# ATSAME51J18A register map
Vendor: Microchip Technology; Series: SAME51; File version: 0
CPU: CM4 r0p1, selectable endian, MPU, FPU, 3 interrupt priority bits
Registers are 32-bit, read-write, reset 0x0 unless marked. A register's access mark holds for its fields unless they carry their own. Offsets are from the block's base; [hi:lo] are bit positions; lines under a group give offsets from that group; {n}, {i} and the like mark numbered series; 'fields as' and 'values as' point back to an identical list.

## USB — Universal Serial Bus
Base 0x41000000; register names take the prefix USB_
0x00 DEVICE group — USB is Device
  0x00 CTRLA 8-bit — Control A
    [7] MODE — Operating Mode
      0=DEVICE (Device Mode); 1=HOST (Host Mode)
    [2] RUNSTDBY — Run in Standby Mode
    [1] ENABLE
    [0] SWRST — Software Reset
  0x02 SYNCBUSY 8-bit ro — Synchronization Busy
    [1] ENABLE — Enable Synchronization Busy
    [0] SWRST — Software Reset Synchronization Busy
  0x03 QOSCTRL 8-bit reset 0xF — USB Quality Of Service
    [3:2] DQOS — Data Quality of Service
    [1:0] CQOS — Configuration Quality of Service
  0x08 CTRLB 16-bit reset 0x1 — DEVICE Control B
    [11:10] LPMHDSK — Link Power Management Handshake
      0=NO (No handshake. LPM is not supported); 1=ACK; 2=NYET; 3=STALL
    [9] GNAK — Global NAK
    [8] OPMODE2 — Specific Operational Mode
    [7] TSTPCKT — Test packet mode
    [6] TSTK — Test mode K
    [5] TSTJ — Test mode J
    [4] NREPLY — No Reply
    [3:2] SPDCONF — Speed Configuration
      0=FS (FS : Full Speed); 1=LS (LS : Low Speed); 2=HS (HS : High Speed capable); 3=HSTM (HSTM: High Speed Test Mode (force high-speed mode for test mode))
    [1] UPRSM — Upstream Resume
    [0] DETACH
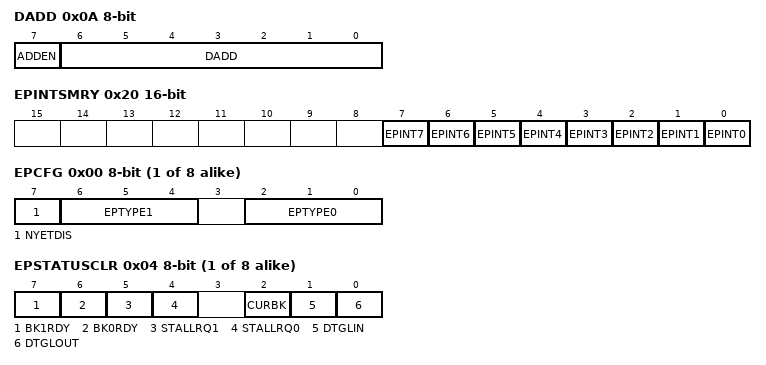
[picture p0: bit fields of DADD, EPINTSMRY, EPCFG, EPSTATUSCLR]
  0x0A DADD 8-bit — DEVICE Device Address
    [7] ADDEN — Device Address Enable
    [6:0] DADD — Device Address
  0x0C STATUS 8-bit ro reset 0x40 — DEVICE Status
    [7:6] LINESTATE — USB Line State Status
      0=SE0/RESET; 1=FS-J or LS-K State; 2=FS-K or LS-J State
    [3:2] SPEED — Speed Status
      0=FS (Full-speed mode); 1=LS (Low-speed mode); 2=HS (High-speed mode)
  0x0D FSMSTATUS 8-bit ro reset 0x1 — Finite State Machine Status
    [6:0] FSMSTATE — Fine State Machine Status
      1=OFF (OFF (L3). It corresponds to the powered-off, disconnected, and disabled state); 2=ON (ON (L0). It corresponds to the Idle and Active states); 4=SUSPEND (SUSPEND (L2)); 8=SLEEP (SLEEP (L1)); 16=DNRESUME (DNRESUME. Down Stream Resume.); 32=UPRESUME (UPRESUME. Up Stream Resume.); 64=RESET (RESET. USB lines Reset.)
  0x10 FNUM 16-bit ro — DEVICE Device Frame Number
    [15] FNCERR — Frame Number CRC Error
    [13:3] FNUM — Frame Number
    [2:0] MFNUM — Micro Frame Number
  0x14 INTENCLR 16-bit — DEVICE Device Interrupt Enable Clear
    [9] LPMSUSP — Link Power Management Suspend Interrupt Enable
    [8] LPMNYET — Link Power Management Not Yet Interrupt Enable
    [7] RAMACER — Ram Access Interrupt Enable
    [6] UPRSM — Upstream Resume Interrupt Enable
    [5] EORSM — End Of Resume Interrupt Enable
    [4] WAKEUP — Wake Up Interrupt Enable
    [3] EORST — End of Reset Interrupt Enable
    [2] SOF — Start Of Frame Interrupt Enable
    [1] MSOF — Micro Start of Frame Interrupt Enable in High Speed Mode
    [0] SUSPEND — Suspend Interrupt Enable
  0x18 INTENSET 16-bit — DEVICE Device Interrupt Enable Set
    fields as DEVICE.INTENCLR
  0x1C INTFLAG 16-bit — DEVICE Device Interrupt Flag
    [9] LPMSUSP write-1-clears — Link Power Management Suspend
    [8] LPMNYET write-1-clears — Link Power Management Not Yet
    [7] RAMACER write-1-clears — Ram Access
    [6] UPRSM write-1-clears — Upstream Resume
    [5] EORSM write-1-clears — End Of Resume
    [4] WAKEUP write-1-clears
    [3] EORST write-1-clears — End of Reset
    [2] SOF write-1-clears — Start Of Frame
    [1] MSOF — Micro Start of Frame in High Speed Mode
    [0] SUSPEND write-1-clears
  0x20 EPINTSMRY 16-bit ro — DEVICE End Point Interrupt Summary
    [n] EPINT{n} (n=0..7) — End Point {n} Interrupt
  0x24 DESCADD — Descriptor Address
    [31:0] DESCADD — Descriptor Address Value
  0x28 PADCAL 16-bit — USB PAD Calibration
    [14:12] TRIM — USB Pad Trim calibration
    [10:6] TRANSN — USB Pad Transn calibration
    [4:0] TRANSP — USB Pad Transp calibration
  {0x100+0x20*j} DEVICE_ENDPOINT[{j}] (j=0..7) group
    0x00 EPCFG 8-bit — DEVICE_ENDPOINT End Point Configuration
      [7] NYETDIS — NYET Token Disable
      [6:4] EPTYPE1 — End Point Type1
      [2:0] EPTYPE0 — End Point Type0
    0x04 EPSTATUSCLR 8-bit wo — DEVICE_ENDPOINT End Point Pipe Status Clear
      [7] BK1RDY — Bank 1 Ready Clear
      [6] BK0RDY — Bank 0 Ready Clear
      [5] STALLRQ1 — Stall 1 Request Clear
      [4] STALLRQ0 — Stall 0 Request Clear
      [2] CURBK — Current Bank Clear
      [1] DTGLIN — Data Toggle IN Clear
      [0] DTGLOUT — Data Toggle OUT Clear
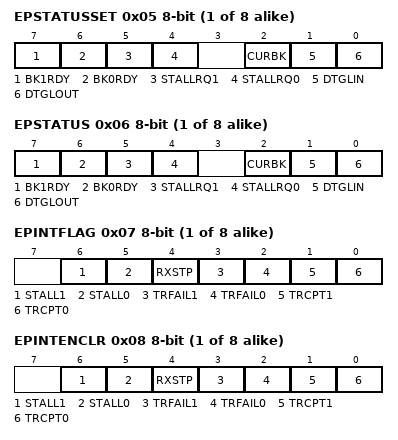
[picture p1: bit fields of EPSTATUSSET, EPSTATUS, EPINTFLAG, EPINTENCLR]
    0x05 EPSTATUSSET 8-bit wo — DEVICE_ENDPOINT End Point Pipe Status Set
      [7] BK1RDY — Bank 1 Ready Set
      [6] BK0RDY — Bank 0 Ready Set
      [5] STALLRQ1 — Stall 1 Request Set
      [4] STALLRQ0 — Stall 0 Request Set
      [2] CURBK — Current Bank Set
      [1] DTGLIN — Data Toggle IN Set
      [0] DTGLOUT — Data Toggle OUT Set
    0x06 EPSTATUS 8-bit ro — DEVICE_ENDPOINT End Point Pipe Status
      [7] BK1RDY — Bank 1 ready
      [6] BK0RDY — Bank 0 ready
      [5] STALLRQ1 — Stall 1 Request
      [4] STALLRQ0 — Stall 0 Request
      [2] CURBK — Current Bank
      [1] DTGLIN — Data Toggle In
      [0] DTGLOUT — Data Toggle Out
    0x07 EPINTFLAG 8-bit — DEVICE_ENDPOINT End Point Interrupt Flag
      [6] STALL1 write-1-clears — Stall 1 In/out
      [5] STALL0 write-1-clears — Stall 0 In/out
      [4] RXSTP write-1-clears — Received Setup
      [3] TRFAIL1 write-1-clears — Error Flow 1
      [2] TRFAIL0 write-1-clears — Error Flow 0
      [1] TRCPT1 write-1-clears — Transfer Complete 1
      [0] TRCPT0 write-1-clears — Transfer Complete 0
    0x08 EPINTENCLR 8-bit — DEVICE_ENDPOINT End Point Interrupt Clear Flag
      [6] STALL1 — Stall 1 In/Out Interrupt Disable
      [5] STALL0 — Stall 0 In/Out Interrupt Disable
      [4] RXSTP — Received Setup Interrupt Disable
      [3] TRFAIL1 — Error Flow 1 Interrupt Disable
      [2] TRFAIL0 — Error Flow 0 Interrupt Disable
      [1] TRCPT1 — Transfer Complete 1 Interrupt Disable
      [0] TRCPT0 — Transfer Complete 0 Interrupt Disable
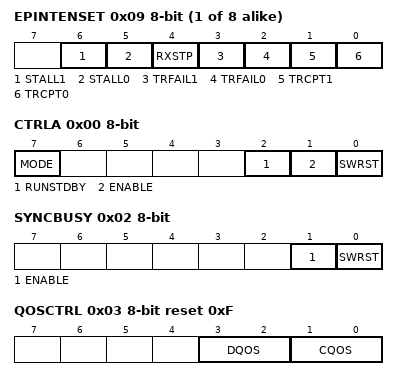
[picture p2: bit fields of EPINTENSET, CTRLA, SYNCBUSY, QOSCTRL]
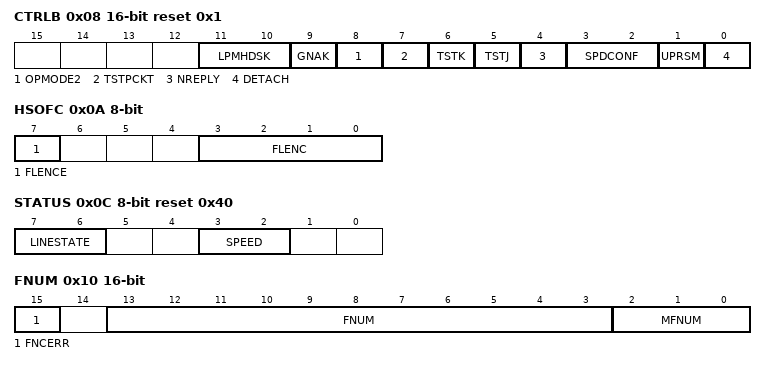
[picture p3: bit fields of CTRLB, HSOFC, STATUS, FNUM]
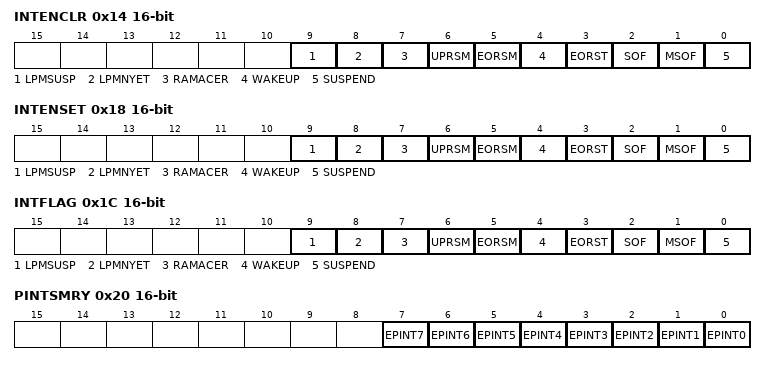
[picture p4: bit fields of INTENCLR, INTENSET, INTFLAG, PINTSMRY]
    0x09 EPINTENSET 8-bit — DEVICE_ENDPOINT End Point Interrupt Set Flag
      [6] STALL1 — Stall 1 In/out Interrupt enable
      [5] STALL0 — Stall 0 In/out Interrupt enable
      [4] RXSTP — Received Setup Interrupt Enable
      [3] TRFAIL1 — Error Flow 1 Interrupt Enable
      [2] TRFAIL0 — Error Flow 0 Interrupt Enable
      [1] TRCPT1 — Transfer Complete 1 Interrupt Enable
      [0] TRCPT0 — Transfer Complete 0 Interrupt Enable
0x00 HOST group (alternate view of DEVICE) — USB is Host
  0x00 CTRLA 8-bit — Control A
    fields as DEVICE.CTRLA
  0x02 SYNCBUSY 8-bit ro — Synchronization Busy
    fields as DEVICE.SYNCBUSY
  0x03 QOSCTRL 8-bit reset 0xF — USB Quality Of Service
    fields as DEVICE.QOSCTRL
  0x08 CTRLB 16-bit — HOST Control B
    [11] L1RESUME — Send L1 Resume
    [10] VBUSOK — VBUS is OK
    [9] BUSRESET — Send USB Reset
    [8] SOFE — Start of Frame Generation Enable
    [6] TSTK — Test mode K
    [5] TSTJ — Test mode J
    [4] AUTORESUME — Auto Resume Enable
    [3:2] SPDCONF — Speed Configuration for Host
      0=NORMAL (Normal mode: the host starts in full-speed mode and performs a high-speed reset to switch to the high speed mode if the downstream peripheral is high-speed capable.); 3=FS (Full-speed: the host remains in full-speed mode whatever is the peripheral speed capability. Relevant in UTMI mode only.)
    [1] RESUME — Send USB Resume
  0x0A HSOFC 8-bit — HOST Host Start Of Frame Control
    [7] FLENCE — Frame Length Control Enable
    [3:0] FLENC — Frame Length Control
  0x0C STATUS 8-bit — HOST Status
    [7:6] LINESTATE — USB Line State Status
    [3:2] SPEED — Speed Status
  0x0D FSMSTATUS 8-bit ro reset 0x1 — Finite State Machine Status
    fields as DEVICE.FSMSTATUS
  0x10 FNUM 16-bit — HOST Host Frame Number
    [13:3] FNUM — Frame Number
    [2:0] MFNUM — Micro Frame Number
  0x12 FLENHIGH 8-bit ro — HOST Host Frame Length
    [7:0] FLENHIGH — Frame Length
  0x14 INTENCLR 16-bit — HOST Host Interrupt Enable Clear
    [9] DDISC — Device Disconnection Interrupt Disable
    [8] DCONN — Device Connection Interrupt Disable
    [7] RAMACER — Ram Access Interrupt Disable
    [6] UPRSM — Upstream Resume from Device Interrupt Disable
    [5] DNRSM — DownStream to Device Interrupt Disable
    [4] WAKEUP — Wake Up Interrupt Disable
    [3] RST — BUS Reset Interrupt Disable
    [2] HSOF — Host Start Of Frame Interrupt Disable
  0x18 INTENSET 16-bit — HOST Host Interrupt Enable Set
    [9] DDISC — Device Disconnection Interrupt Enable
    [8] DCONN — Link Power Management Interrupt Enable
    [7] RAMACER — Ram Access Interrupt Enable
    [6] UPRSM — Upstream Resume fromthe device Interrupt Enable
    [5] DNRSM — DownStream to the Device Interrupt Enable
    [4] WAKEUP — Wake Up Interrupt Enable
    [3] RST — Bus Reset Interrupt Enable
    [2] HSOF — Host Start Of Frame Interrupt Enable
  0x1C INTFLAG 16-bit — HOST Host Interrupt Flag
    [9] DDISC write-1-clears — Device Disconnection
    [8] DCONN write-1-clears — Device Connection
    [7] RAMACER write-1-clears — Ram Access
    [6] UPRSM write-1-clears — Upstream Resume from the Device
    [5] DNRSM write-1-clears — Downstream
    [4] WAKEUP write-1-clears
    [3] RST write-1-clears — Bus Reset
    [2] HSOF write-1-clears — Host Start Of Frame
  0x20 PINTSMRY 16-bit ro — HOST Pipe Interrupt Summary
    [n] EPINT{n} (n=0..7) — Pipe {n} Interrupt
  0x24 DESCADD — Descriptor Address
    [31:0] DESCADD — Descriptor Address Value
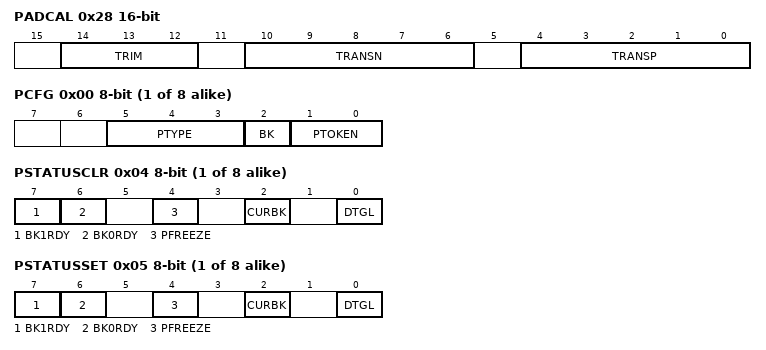
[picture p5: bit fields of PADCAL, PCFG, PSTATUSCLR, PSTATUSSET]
  0x28 PADCAL 16-bit — USB PAD Calibration
    fields as DEVICE.PADCAL
  {0x100+0x20*j} HOST_PIPE[{j}] (j=0..7) group
    0x00 PCFG 8-bit — HOST_PIPE End Point Configuration
      [5:3] PTYPE — Pipe Type
      [2] BK — Pipe Bank
      [1:0] PTOKEN — Pipe Token
    0x03 BINTERVAL 8-bit — HOST_PIPE Bus Access Period of Pipe
      [7:0] BITINTERVAL
    0x04 PSTATUSCLR 8-bit wo — HOST_PIPE End Point Pipe Status Clear
      [7] BK1RDY — Bank 1 Ready Clear
      [6] BK0RDY — Bank 0 Ready Clear
      [4] PFREEZE — Pipe Freeze Clear
      [2] CURBK — Curren Bank clear
      [0] DTGL — Data Toggle clear
    0x05 PSTATUSSET 8-bit wo — HOST_PIPE End Point Pipe Status Set
      [7] BK1RDY — Bank 1 Ready Set
      [6] BK0RDY — Bank 0 Ready Set
      [4] PFREEZE — Pipe Freeze Set
      [2] CURBK — Current Bank Set
      [0] DTGL — Data Toggle Set
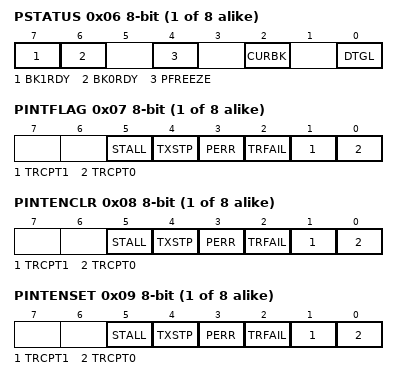
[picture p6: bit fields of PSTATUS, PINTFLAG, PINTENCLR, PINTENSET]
    0x06 PSTATUS 8-bit ro — HOST_PIPE End Point Pipe Status
      [7] BK1RDY — Bank 1 ready
      [6] BK0RDY — Bank 0 ready
      [4] PFREEZE — Pipe Freeze
      [2] CURBK — Current Bank
      [0] DTGL — Data Toggle
    0x07 PINTFLAG 8-bit — HOST_PIPE Pipe Interrupt Flag
      [5] STALL write-1-clears — Stall Interrupt Flag
      [4] TXSTP write-1-clears — Transmit Setup Interrupt Flag
      [3] PERR write-1-clears — Pipe Error Interrupt Flag
      [2] TRFAIL write-1-clears — Error Flow Interrupt Flag
      [1] TRCPT1 write-1-clears — Transfer Complete 1 Interrupt Flag
      [0] TRCPT0 write-1-clears — Transfer Complete 0 Interrupt Flag
    0x08 PINTENCLR 8-bit — HOST_PIPE Pipe Interrupt Flag Clear
      [5] STALL — Stall Inetrrupt Disable
      [4] TXSTP — Transmit Setup Interrupt Disable
      [3] PERR — Pipe Error Interrupt Disable
      [2] TRFAIL — Error Flow Interrupt Disable
      [1] TRCPT1 — Transfer Complete 1 Disable
      [0] TRCPT0 — Transfer Complete 0 Disable
    0x09 PINTENSET 8-bit — HOST_PIPE Pipe Interrupt Flag Set
      [5] STALL — Stall Interrupt Enable
      [4] TXSTP — Transmit Setup Interrupt Enable
      [3] PERR — Pipe Error Interrupt Enable
      [2] TRFAIL — Error Flow Interrupt Enable
      [1] TRCPT1 — Transfer Complete 1 Interrupt Enable
      [0] TRCPT0 — Transfer Complete 0 Interrupt Enable
